# RZT2L register map
Vendor: Renesas Electronics Corporation; Series: RZT; File version: 1.20.00
CPU: other r0p0, little endian, MPU, no FPU, VTOR, 4 interrupt priority bits, 624 interrupts
Registers are 32-bit, read-write, reset 0x0 unless marked. A register's access mark holds for its fields unless they carry their own. Offsets are from the block's base; [hi:lo] are bit positions; {n}, {i} and the like mark numbered series.

## AFMT0 — A-format Unit 0
Base 0x90045000
Same registers: AFMT1 0x90055000
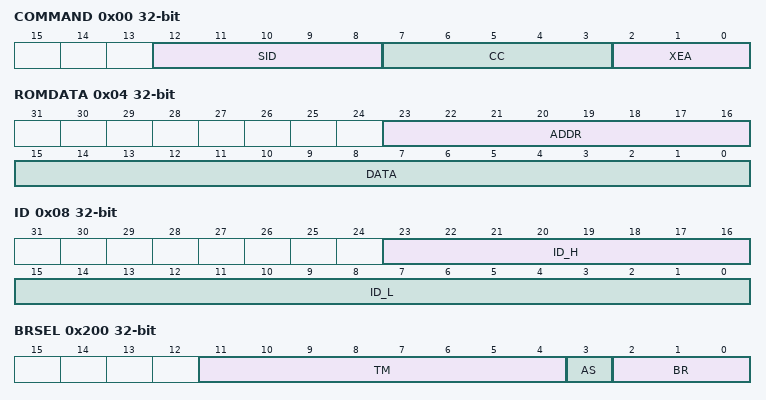
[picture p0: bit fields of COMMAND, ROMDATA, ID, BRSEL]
0x00 COMMAND wo — Command Code Encoder Address Register
  [12:8] SID — Subcommand ID
  [7:3] CC — Command code
  [2:0] XEA — Encoder address
0x00 ENC{i}RXDATA0 (i=1..8; step 0x20) ro — ENC{i} Receive Data 0 Register
  [31:0] DATA — Encoder read data
0x04 ENC{i}RXDATA1 (i=1..8; step 0x20) ro — ENC{i} Receive Data 1 Register
  [31:0] DATA — Encoder read data
0x04 ROMDATA wo — EEPROM Address and Write Data Register
  [23:16] ADDR — 8-bit EEPROM address
  [15:0] DATA — 16-bit EEPROM data
0x08 ENC{i}RXDATA2 (i=1..8; step 0x20) ro — ENC{i} Receive Data 2 Register
  [31:0] DATA — Encoder read data
0x08 ID wo — ID Code Register
  [23:16] ID_H — 24-bit ID code, high byte
  [15:0] ID_L — 24-bit ID code, low word
0x0C ENC{i}RXDATA3 (i=1..8; step 0x20) ro — ENC{i} Receive Data 3 Register
  [31:0] DATA — Encoder read data
0x10 ENC{i}RXDATA4 (i=1..8; step 0x20) ro — ENC{i} Receive Data 4 Register
  [31:0] DATA — Encoder read data
0x14 ENC{i}RXDATA5 (i=1..8; step 0x20) ro — ENC{i} Receive Data 5 Register
  [31:0] DATA — Encoder read data
0x18 ENC{i}RXDATA6 (i=1..8; step 0x20) ro — ENC{i} Receive Data 6 Register
  [31:0] DATA — Encoder read data
0x1C ENC{i}RXDATA7 (i=1..8; step 0x20) ro — ENC{i} Receive Data 7 Register
  [31:0] DATA — Encoder read data
0x100 TRGSEL wo — Trigger Select Register
  [0] EXT — Trigger select
    0=Set TRG bit in ENCnTXSEL register; 1=Trigger from ELC
0x104 TXTRG wo — Transmission Trigger Register
  [0] TRG — Command data transmission trigger generation
    0=Do nothing; 1=Transmission trigger is generated
0x200 BRSEL wo — Baud Rate Setting Register
  [11:4] TM — t2 time setting N
  [3] AS — A-Safety enable
    0=Disable; 1=Enable
  [2:0] BR — Baud rate setting
    0=2.5 Mbps; 1=4 Mbps; 2=6.67 Mbps; 3=8 Mbps; 4=16 Mbps; other=Others (Setting prohibited)

## ENCOUT — Encoder Divided-Output Module
Base 0x90060000
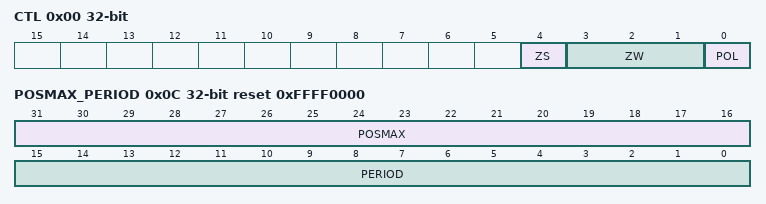
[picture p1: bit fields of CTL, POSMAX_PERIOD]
0x00 CTL — Control Register
  [4] ZS — Synchronization phase of Phase Z
    0=Phase A; 1=Phase B
  [3:1] ZW — Pulse Width of Phase Z
    0=Disable Phase Z output; 1=Pulse output when current position, POSCNT, is 0; 2=Pulse output when current position, POSCNT, is -1 and 0 (sync with Phase A) Pulse output when current position, POSCNT, is 0 and 1 (sync with Phase B); 3=Pulse output when current position, POSCNT, is -1, 0 and 1; 4=Pulse output when current position, POSCNT, is -1, 0, 1 and 2 (sync with Phase A) Pulse output when current position, POSCNT, is -2, -1, 0 and 1 (sync with Phase B); other=Others (Disable Phase Z output)
  [0] POL — Polarity of Phase B
    0=Positive phase; 1=Reversed phase
0x04 STR — Start Register
  [0] ENCE — ENCOUT Operation Start
    0=ENCOUT operation stop; 1=ENCOUT operation start
0x0C POSMAX_PERIOD reset 0xFFFF0000 — Maximum Position and Carrier Period Register
  [31:16] POSMAX — Maximum Position Setting
  [15:0] PERIOD — Carrier Period Setting
0x10 OUTCNT — Output Count Register
  [15:0] EDGCNT — Edge Count Setting
0x14 POSCNT — Position Count Register
  [15:0] POSCNT — Current Position

## GSC — Global System Counter
Base 0xC0060000
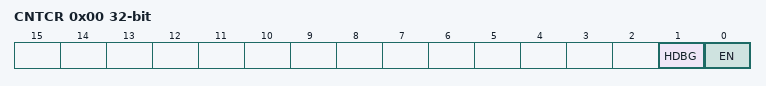
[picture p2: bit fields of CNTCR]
0x00 CNTCR — Global System Counter Control Register
  [1] HDBG — Halt on Debug
    0=Do not halt on debug, HLTDBG signal into the counter has no effect; 1=Halt on debug, when HLTDBG is driven high, the count value is held static
  [0] EN — Counter Enable
    0=The counter is disabled and not incrementing; 1=The counter is enabled and is incrementing
0x04 CNTSR ro — Global System Counter Status Register
  [1] DBGH — Debug Halted
    0=Not halt on debug; 1=Halt on debug
0x08 CNTCVL — Global System Counter Current Value Lower Register
  [31:0] CNTCVL_L_32 — Current value of the counter, lower 32 bits
0x0C CNTCVU — Global System Counter Current Value Upper Register
  [31:0] CNTCVU_U_32 — Current value of the counter, upper 32 bits
0x20 CNTFID0 — Global System Counter Base Frequency ID Register
  [31:0] FREQ — Frequency in number of ticks per second
